# PIC32MX470F512H register map
Registers are 32-bit, access not given, reset 0x0 unless marked. A register's access mark holds for its fields unless they carry their own. Offsets are from the block's base; [hi:lo] are bit positions; {n}, {i} and the like mark numbered series.

## PORTD — PORTD peripheral
Base 0xBF886300
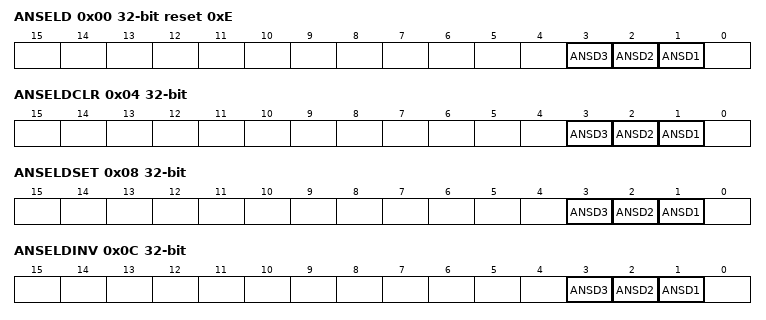
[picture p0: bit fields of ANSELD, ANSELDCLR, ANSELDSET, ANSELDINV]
0x00 ANSELD reset 0xE
  [3] ANSD3, [2] ANSD2, [1] ANSD1
0x04 ANSELDCLR
  [3] ANSD3, [2] ANSD2, [1] ANSD1
0x08 ANSELDSET
  [3] ANSD3, [2] ANSD2, [1] ANSD1
0x0C ANSELDINV
  [3] ANSD3, [2] ANSD2, [1] ANSD1
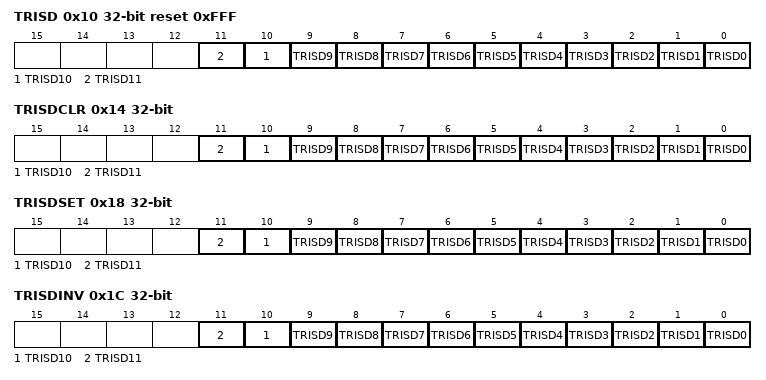
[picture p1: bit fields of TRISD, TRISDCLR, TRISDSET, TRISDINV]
0x10 TRISD reset 0xFFF
  [n] TRISD{n} (n=0..11)
0x14 TRISDCLR
  [n] TRISD{n} (n=0..11)
0x18 TRISDSET
  [n] TRISD{n} (n=0..11)
0x1C TRISDINV
  [n] TRISD{n} (n=0..11)
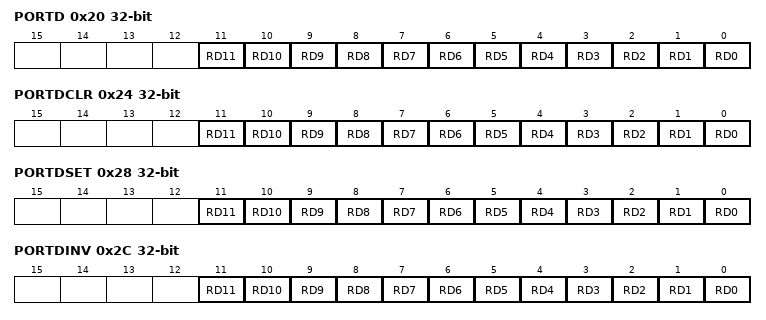
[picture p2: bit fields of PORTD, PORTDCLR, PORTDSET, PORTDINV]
0x20 PORTD
  [n] RD{n} (n=0..11)
0x24 PORTDCLR
  [n] RD{n} (n=0..11)
0x28 PORTDSET
  [n] RD{n} (n=0..11)
0x2C PORTDINV
  [n] RD{n} (n=0..11)
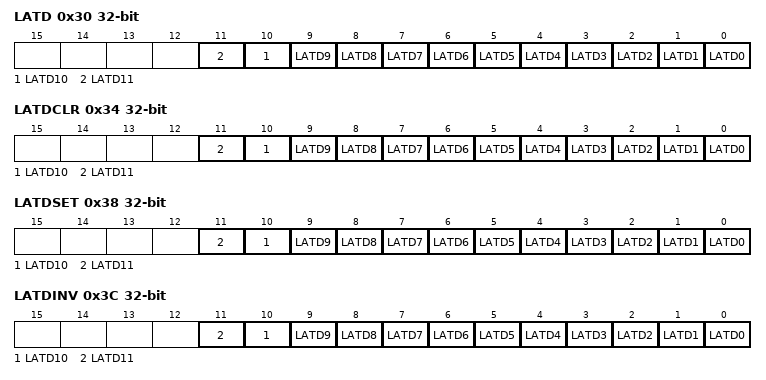
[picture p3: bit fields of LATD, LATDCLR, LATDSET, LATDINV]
0x30 LATD
  [n] LATD{n} (n=0..11)
0x34 LATDCLR
  [n] LATD{n} (n=0..11)
0x38 LATDSET
  [n] LATD{n} (n=0..11)
0x3C LATDINV
  [n] LATD{n} (n=0..11)
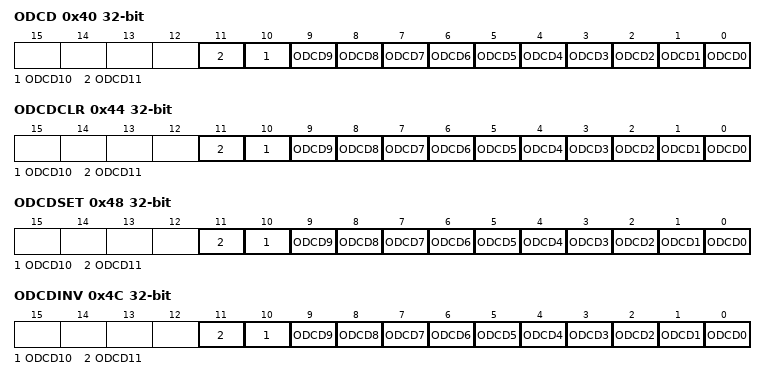
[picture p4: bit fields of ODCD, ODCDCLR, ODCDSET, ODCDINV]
0x40 ODCD
  [n] ODCD{n} (n=0..11)
0x44 ODCDCLR
  [n] ODCD{n} (n=0..11)
0x48 ODCDSET
  [n] ODCD{n} (n=0..11)
0x4C ODCDINV
  [n] ODCD{n} (n=0..11)
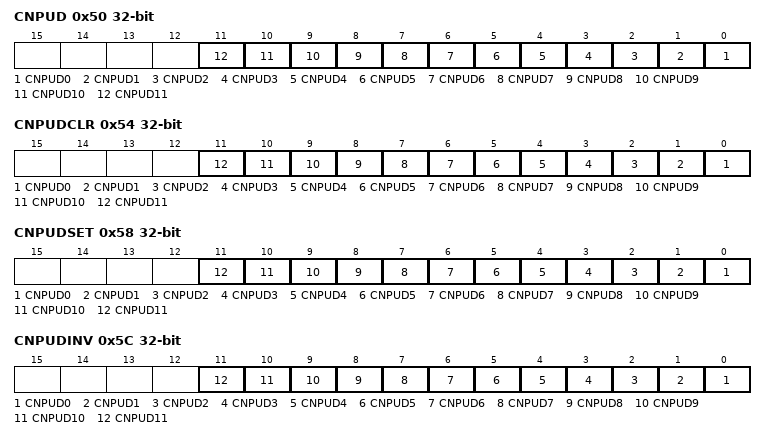
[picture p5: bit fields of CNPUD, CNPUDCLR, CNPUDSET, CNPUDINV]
0x50 CNPUD
  [n] CNPUD{n} (n=0..11)
0x54 CNPUDCLR
  [n] CNPUD{n} (n=0..11)
0x58 CNPUDSET
  [n] CNPUD{n} (n=0..11)
0x5C CNPUDINV
  [n] CNPUD{n} (n=0..11)
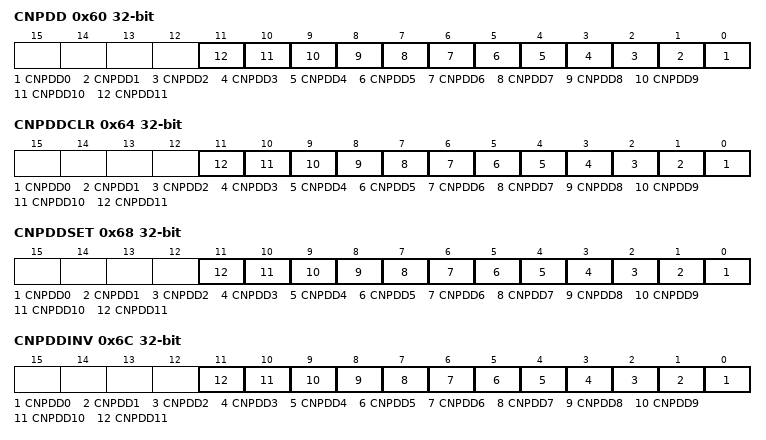
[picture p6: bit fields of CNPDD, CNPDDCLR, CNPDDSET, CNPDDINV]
0x60 CNPDD
  [n] CNPDD{n} (n=0..11)
0x64 CNPDDCLR
  [n] CNPDD{n} (n=0..11)
0x68 CNPDDSET
  [n] CNPDD{n} (n=0..11)
0x6C CNPDDINV
  [n] CNPDD{n} (n=0..11)
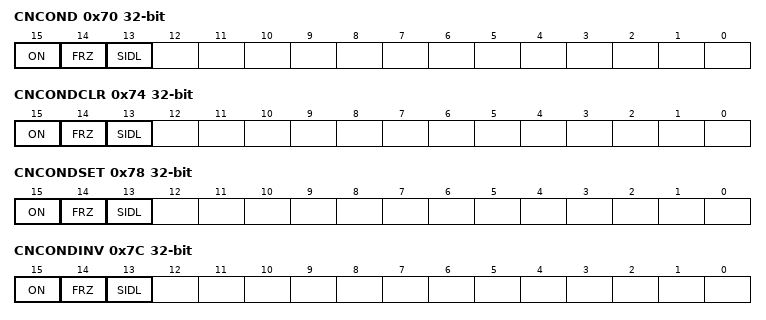
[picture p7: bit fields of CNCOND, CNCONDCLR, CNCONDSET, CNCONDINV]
0x70 CNCOND
  [15] ON, [14] FRZ, [13] SIDL
0x74 CNCONDCLR
  [15] ON, [14] FRZ, [13] SIDL
0x78 CNCONDSET
  [15] ON, [14] FRZ, [13] SIDL
0x7C CNCONDINV
  [15] ON, [14] FRZ, [13] SIDL
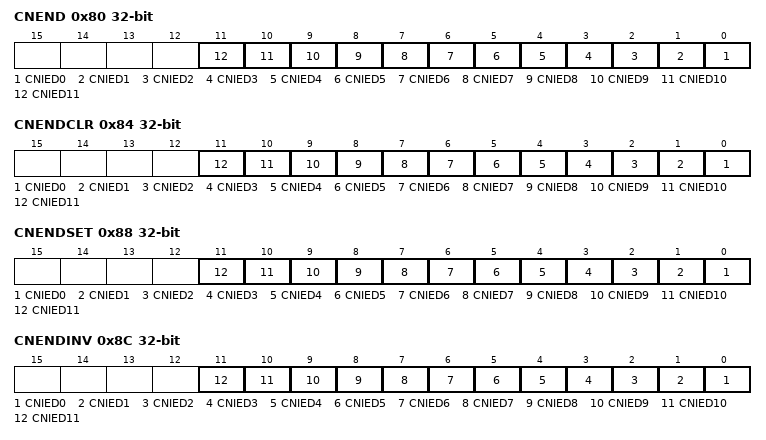
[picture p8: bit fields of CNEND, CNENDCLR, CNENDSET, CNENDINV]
0x80 CNEND
  [n] CNIED{n} (n=0..11)
0x84 CNENDCLR
  [n] CNIED{n} (n=0..11)
0x88 CNENDSET
  [n] CNIED{n} (n=0..11)
0x8C CNENDINV
  [n] CNIED{n} (n=0..11)
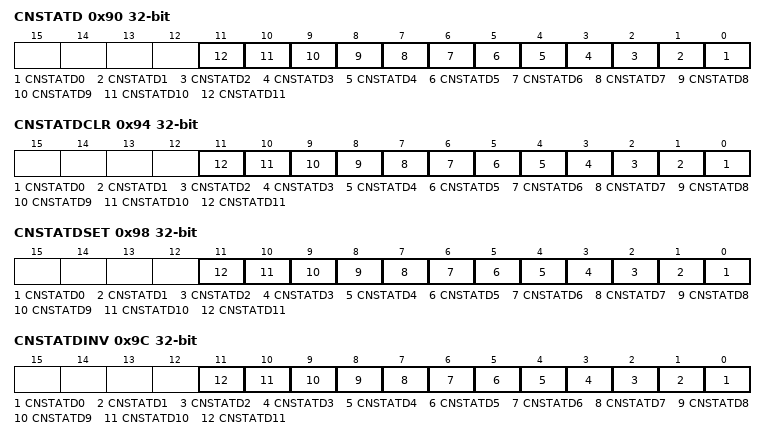
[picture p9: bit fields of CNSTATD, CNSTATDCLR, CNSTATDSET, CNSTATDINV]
0x90 CNSTATD
  [n] CNSTATD{n} (n=0..11)
0x94 CNSTATDCLR
  [n] CNSTATD{n} (n=0..11)
0x98 CNSTATDSET
  [n] CNSTATD{n} (n=0..11)
0x9C CNSTATDINV
  [n] CNSTATD{n} (n=0..11)

## PORTE — PORTE peripheral
Base 0xBF886400
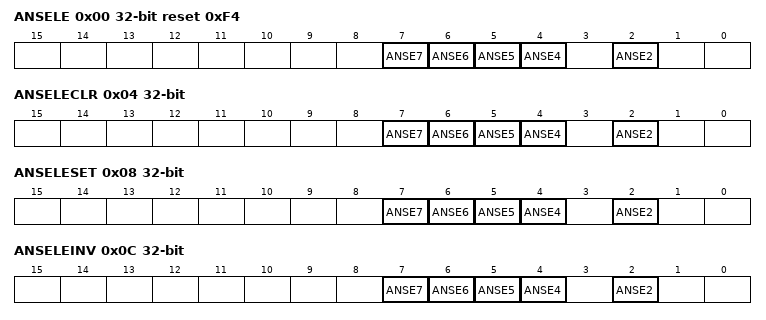
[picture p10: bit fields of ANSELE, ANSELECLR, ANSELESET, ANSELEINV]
0x00 ANSELE reset 0xF4
  [n] ANSE{n} (n=4..7), [2] ANSE2
0x04 ANSELECLR
  [n] ANSE{n} (n=4..7), [2] ANSE2
0x08 ANSELESET
  [n] ANSE{n} (n=4..7), [2] ANSE2
0x0C ANSELEINV
  [n] ANSE{n} (n=4..7), [2] ANSE2
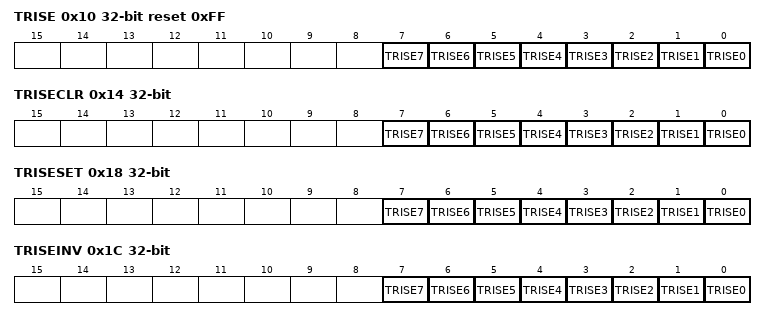
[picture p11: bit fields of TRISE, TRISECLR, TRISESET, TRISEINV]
0x10 TRISE reset 0xFF
  [n] TRISE{n} (n=0..7)
0x14 TRISECLR
  [n] TRISE{n} (n=0..7)
0x18 TRISESET
  [n] TRISE{n} (n=0..7)
0x1C TRISEINV
  [n] TRISE{n} (n=0..7)
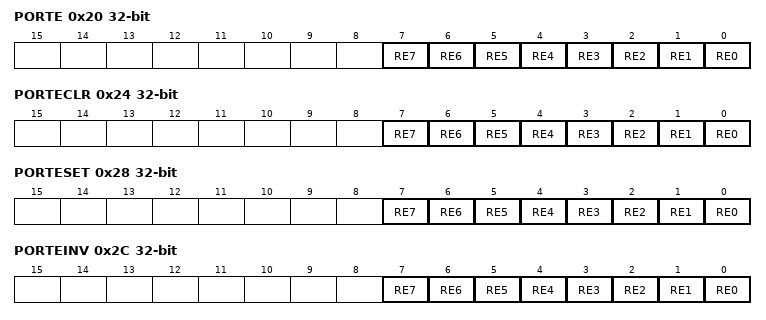
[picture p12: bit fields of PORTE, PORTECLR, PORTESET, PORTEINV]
0x20 PORTE
  [n] RE{n} (n=0..7)
0x24 PORTECLR
  [n] RE{n} (n=0..7)
0x28 PORTESET
  [n] RE{n} (n=0..7)
0x2C PORTEINV
  [n] RE{n} (n=0..7)
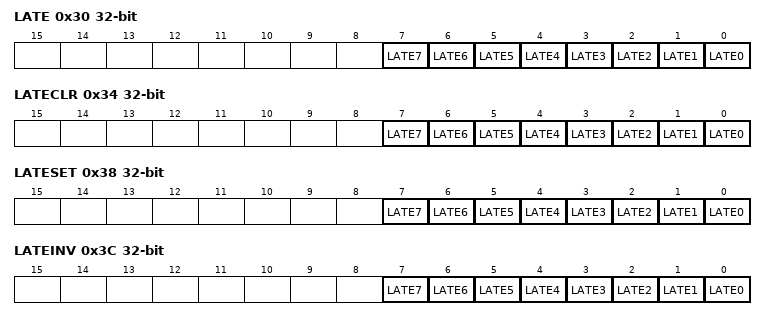
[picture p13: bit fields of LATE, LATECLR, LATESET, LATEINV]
0x30 LATE
  [n] LATE{n} (n=0..7)
0x34 LATECLR
  [n] LATE{n} (n=0..7)
0x38 LATESET
  [n] LATE{n} (n=0..7)
0x3C LATEINV
  [n] LATE{n} (n=0..7)
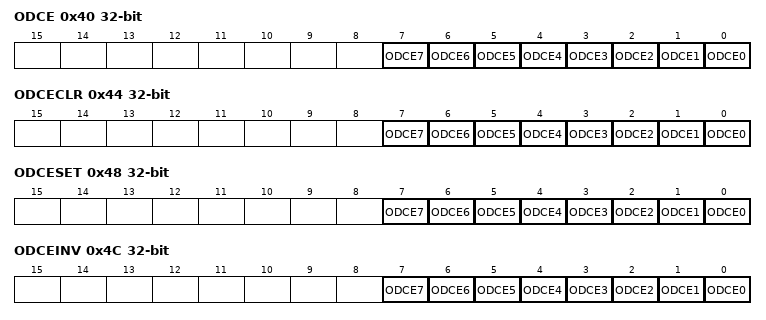
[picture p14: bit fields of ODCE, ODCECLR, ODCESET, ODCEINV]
0x40 ODCE
  [n] ODCE{n} (n=0..7)
0x44 ODCECLR
  [n] ODCE{n} (n=0..7)
0x48 ODCESET
  [n] ODCE{n} (n=0..7)
0x4C ODCEINV
  [n] ODCE{n} (n=0..7)
0x50 CNPUE
  [n] CNPUE{n} (n=0..7)
0x54 CNPUECLR
  [n] CNPUE{n} (n=0..7)
0x58 CNPUESET
  [n] CNPUE{n} (n=0..7)
0x5C CNPUEINV
  [n] CNPUE{n} (n=0..7)
0x60 CNPDE
  [n] CNPDE{n} (n=0..7)
0x64 CNPDECLR
  [n] CNPDE{n} (n=0..7)
0x68 CNPDESET
  [n] CNPDE{n} (n=0..7)
0x6C CNPDEINV
  [n] CNPDE{n} (n=0..7)
0x70 CNCONE
  [15] ON, [14] FRZ, [13] SIDL
0x74 CNCONECLR
  [15] ON, [14] FRZ, [13] SIDL
0x78 CNCONESET
  [15] ON, [14] FRZ, [13] SIDL
0x7C CNCONEINV
  [15] ON, [14] FRZ, [13] SIDL
0x80 CNENE
  [n] CNIEE{n} (n=0..7)
0x84 CNENECLR
  [n] CNIEE{n} (n=0..7)
0x88 CNENESET
  [n] CNIEE{n} (n=0..7)
0x8C CNENEINV
  [n] CNIEE{n} (n=0..7)
0x90 CNSTATE
  [n] CNSTATE{n} (n=0..7)
0x94 CNSTATECLR
  [n] CNSTATE{n} (n=0..7)
0x98 CNSTATESET
  [n] CNSTATE{n} (n=0..7)
0x9C CNSTATEINV
  [n] CNSTATE{n} (n=0..7)

## PORTF — PORTF peripheral
Base 0xBF886500
0x00 ANSELF
0x04 ANSELFCLR
0x08 ANSELFSET
0x0C ANSELFINV
0x10 TRISF reset 0x3B
  [5] TRISF5, [4] TRISF4, [3] TRISF3, [1] TRISF1, [0] TRISF0
0x14 TRISFCLR
  [5] TRISF5, [4] TRISF4, [3] TRISF3, [1] TRISF1, [0] TRISF0
0x18 TRISFSET
  [5] TRISF5, [4] TRISF4, [3] TRISF3, [1] TRISF1, [0] TRISF0
0x1C TRISFINV
  [5] TRISF5, [4] TRISF4, [3] TRISF3, [1] TRISF1, [0] TRISF0
0x20 PORTF
  [5] RF5, [4] RF4, [3] RF3, [1] RF1, [0] RF0
0x24 PORTFCLR
  [5] RF5, [4] RF4, [3] RF3, [1] RF1, [0] RF0
0x28 PORTFSET
  [5] RF5, [4] RF4, [3] RF3, [1] RF1, [0] RF0
0x2C PORTFINV
  [5] RF5, [4] RF4, [3] RF3, [1] RF1, [0] RF0
0x30 LATF
  [5] LATF5, [4] LATF4, [3] LATF3, [1] LATF1, [0] LATF0
0x34 LATFCLR
  [5] LATF5, [4] LATF4, [3] LATF3, [1] LATF1, [0] LATF0
0x38 LATFSET
  [5] LATF5, [4] LATF4, [3] LATF3, [1] LATF1, [0] LATF0
0x3C LATFINV
  [5] LATF5, [4] LATF4, [3] LATF3, [1] LATF1, [0] LATF0
0x40 ODCF
  [5] ODCF5, [4] ODCF4, [3] ODCF3, [1] ODCF1, [0] ODCF0
0x44 ODCFCLR
  [5] ODCF5, [4] ODCF4, [3] ODCF3, [1] ODCF1, [0] ODCF0
0x48 ODCFSET
  [5] ODCF5, [4] ODCF4, [3] ODCF3, [1] ODCF1, [0] ODCF0
0x4C ODCFINV
  [5] ODCF5, [4] ODCF4, [3] ODCF3, [1] ODCF1, [0] ODCF0
0x50 CNPUF
  [5] CNPUF5, [4] CNPUF4, [3] CNPUF3, [1] CNPUF1, [0] CNPUF0
0x54 CNPUFCLR
  [5] CNPUF5, [4] CNPUF4, [3] CNPUF3, [1] CNPUF1, [0] CNPUF0
0x58 CNPUFSET
  [5] CNPUF5, [4] CNPUF4, [3] CNPUF3, [1] CNPUF1, [0] CNPUF0
0x5C CNPUFINV
  [5] CNPUF5, [4] CNPUF4, [3] CNPUF3, [1] CNPUF1, [0] CNPUF0
0x60 CNPDF
  [5] CNPDF5, [4] CNPDF4, [3] CNPDF3, [1] CNPDF1, [0] CNPDF0
0x64 CNPDFCLR
  [5] CNPDF5, [4] CNPDF4, [3] CNPDF3, [1] CNPDF1, [0] CNPDF0
0x68 CNPDFSET
  [5] CNPDF5, [4] CNPDF4, [3] CNPDF3, [1] CNPDF1, [0] CNPDF0
0x6C CNPDFINV
  [5] CNPDF5, [4] CNPDF4, [3] CNPDF3, [1] CNPDF1, [0] CNPDF0
0x70 CNCONF
  [15] ON, [14] FRZ, [13] SIDL
0x74 CNCONFCLR
  [15] ON, [14] FRZ, [13] SIDL
0x78 CNCONFSET
  [15] ON, [14] FRZ, [13] SIDL
0x7C CNCONFINV
  [15] ON, [14] FRZ, [13] SIDL
0x80 CNENF
  [5] CNIEF5, [4] CNIEF4, [3] CNIEF3, [1] CNIEF1, [0] CNIEF0
0x84 CNENFCLR
  [5] CNIEF5, [4] CNIEF4, [3] CNIEF3, [1] CNIEF1, [0] CNIEF0
0x88 CNENFSET
  [5] CNIEF5, [4] CNIEF4, [3] CNIEF3, [1] CNIEF1, [0] CNIEF0
0x8C CNENFINV
  [5] CNIEF5, [4] CNIEF4, [3] CNIEF3, [1] CNIEF1, [0] CNIEF0
0x90 CNSTATF
  [5] CNSTATF5, [4] CNSTATF4, [3] CNSTATF3, [1] CNSTATF1, [0] CNSTATF0
0x94 CNSTATFCLR
  [5] CNSTATF5, [4] CNSTATF4, [3] CNSTATF3, [1] CNSTATF1, [0] CNSTATF0
0x98 CNSTATFSET
  [5] CNSTATF5, [4] CNSTATF4, [3] CNSTATF3, [1] CNSTATF1, [0] CNSTATF0
0x9C CNSTATFINV
  [5] CNSTATF5, [4] CNSTATF4, [3] CNSTATF3, [1] CNSTATF1, [0] CNSTATF0
